AUTOSAR XML (schema 4-2-2)
standard types defined: float32, uint16, uint8
package /DataTypes
  impl type float32_impl: category=VALUE, base-type=float32
  impl type uint16_impl: category=VALUE, base-type=uint16
  impl type uint8_impl: category=VALUE, base-type=uint8
  impl type Speed_T: category=VALUE, base-type=float32
  impl type Status_T: category=VALUE, base-type=uint16
  app type float32_AppView: category=VALUE
  app type Speed_T_AppView: category=VALUE
  app type Gear_T: category=TEXTTABLE, compu {0=PARK, 1=DRIVE}
  application array data type Samples_T: category=ARRAY
    element Element: category=VALUE, type=Speed_T_AppView, array-size-semantics=FIXED-SIZE, max-number-of-elements=4
  application record data type Pose_T: category=STRUCTURE
    application record element x: category=VALUE, type=float32_AppView
    application record element gear: category=VALUE, type=Gear_T
  data type mapping set DataTypeMappingSet
    data-type-maps:
      application-data-type=float32_AppView, implementation-data-type=float32_impl
      application-data-type=Speed_T_AppView, implementation-data-type=Speed_T
package /PortInterfaces
  sender receiver interface IActuatorStatus
    data status: type=Status_T
  client server interface ICalibration
    operation SetOffset
      arg samples: type=Samples_T, direction=IN, server-argument-impl-policy=USE-ARGUMENT-TYPE
      arg raw: type=uint8_impl, direction=OUT, server-argument-impl-policy=USE-ARGUMENT-TYPE
  sender receiver interface IPose
    data pose: type=Pose_T
  sender receiver interface IVehicleSpeed
    data speed: type=Speed_T
package /ComponentTypes
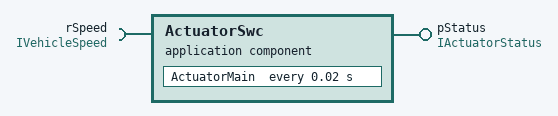
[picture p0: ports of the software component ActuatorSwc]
  application sw component type ActuatorSwc
    provide port pStatus: nonqueued-sender-com-spec=data-element=status, provided-interface=IActuatorStatus
    require port rSpeed: nonqueued-receiver-com-spec{data-element=speed, filter=data-filter-type=ALWAYS}, required-interface=IVehicleSpeed
    behavior ActuatorSwc_InternalBehavior
      timing event TMT_ActuatorMain: start-on-event=ActuatorMain, period=0.02
      port-api-options:
        enable-take-address=false, indirect-api=false, port=pStatus
        enable-take-address=false, indirect-api=false, port=rSpeed
      runnable ActuatorMain
  swc implementation ActuatorSwc_Implementation: behavior=ActuatorSwc_InternalBehavior
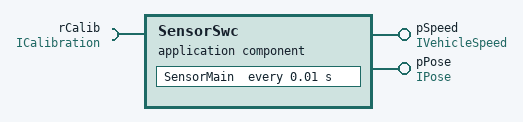
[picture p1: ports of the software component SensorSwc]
  application sw component type SensorSwc
    provide port pSpeed: nonqueued-sender-com-spec=data-element=speed, provided-interface=IVehicleSpeed
    provide port pPose: nonqueued-sender-com-spec=data-element=pose, provided-interface=IPose
    require port rCalib: client-com-spec=SetOffset, required-interface=ICalibration
    behavior SensorSwc_InternalBehavior
      timing event TMT_SensorMain: start-on-event=SensorMain, period=0.01
      init event IT_SensorMain: start-on-event=SensorMain
      port-api-options:
        enable-take-address=false, indirect-api=false, port=pPose
        enable-take-address=false, indirect-api=false, port=pSpeed
        enable-take-address=false, indirect-api=false, port=rCalib
      runnable SensorMain: minimum-start-interval=0.005
  swc implementation SensorSwc_Implementation: behavior=SensorSwc_InternalBehavior
  composition sw component type SwCraftComposition
    component ActuatorSwc: type=ActuatorSwc
    component SensorSwc: type=SensorSwc
    connect SensorSwc.pSpeed -> ActuatorSwc.rSpeed
